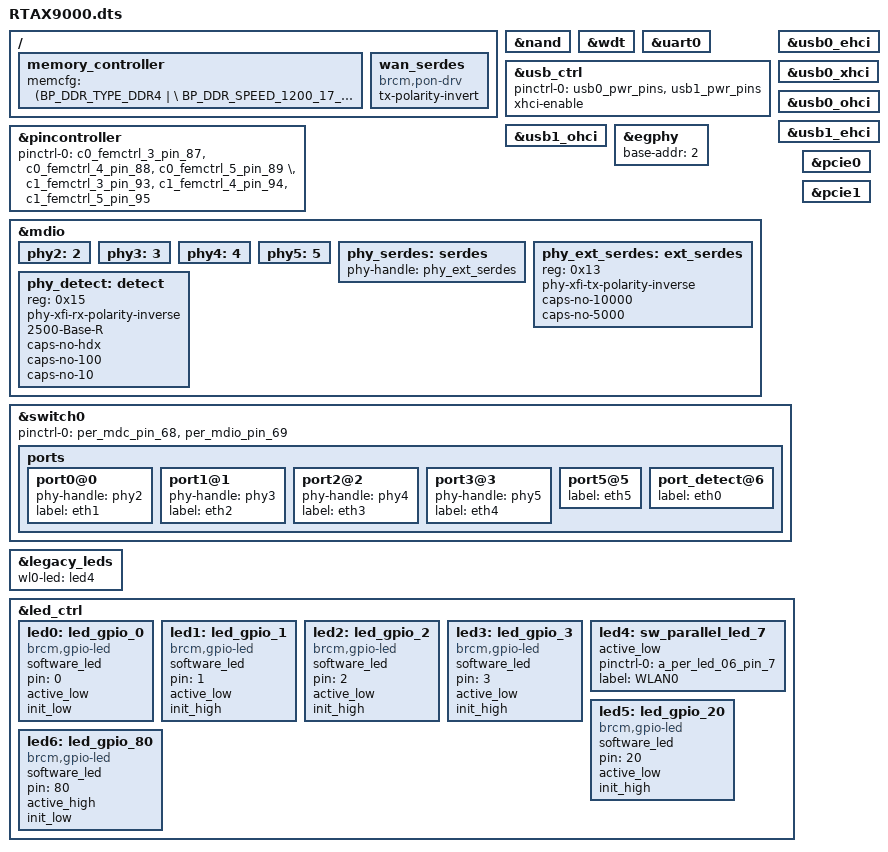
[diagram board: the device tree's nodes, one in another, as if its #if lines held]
#include "inc/6753.dtsi"

/ {
	memory_controller {
		memcfg = <(BP_DDR_TYPE_DDR4            | \
            BP_DDR_SPEED_1200_17_17_17         | \
            BP_DDR_TOTAL_SIZE_512MB            | \
            BP_DDR_DEVICE_WIDTH_16             | \
            BP_DDR_TOTAL_WIDTH_16BIT           | \
            BP_DDR_SSC_CONFIG_1)>;
	};
/*
    buttons {
        compatible = "brcm,buttons";
        reset_button {
            ext_irq = <&bca_extintr 15 BCA_GPIO_ACTIVE_LOW (BCA_EXTINTR_TYPE_LOW_LEVEL | BCA_EXTINTR_TYPE_SENSE_EDGE)>;
            press {
                print = "Button Press -- Hold for 5s to do restore to default";
            };
            hold {
                rst_to_dflt = <5>;
            };
            release {
                reset = <0>;
            };
        };
        ses_button {
            ext_irq = <&bca_extintr 14 BCA_GPIO_ACTIVE_LOW (BCA_EXTINTR_TYPE_LOW_LEVEL | BCA_EXTINTR_TYPE_SENSE_EDGE)>;
            release {
                ses_short_period = <0>;
                ses_long_period = <3>;
            };
        };
    };
*/
    wan_serdes {
        compatible = "brcm,pon-drv";
        tx-polarity-invert;
        status = "okay";
    };
};

&nand {
	status = "okay";
};
&wdt {
	status = "okay";
};
&uart0 {
	status = "okay";
};

&usb_ctrl {
    pinctrl-names = "default";
    pinctrl-0 = <&usb0_pwr_pins &usb1_pwr_pins>;
    xhci-enable;
    status = "okay";
};
&usb0_ehci {
    status = "okay";
};
&usb0_xhci {
    status = "okay";
};
&usb0_ohci {
    status = "okay";
};
&usb1_ehci {
    status = "okay";
};
&usb1_ohci {
    status = "okay";
};

&pincontroller {
    pinctrl-names = "default";
    pinctrl-0 = <&c0_femctrl_3_pin_87 &c0_femctrl_4_pin_88 &c0_femctrl_5_pin_89 \
                 &c1_femctrl_3_pin_93 &c1_femctrl_4_pin_94 &c1_femctrl_5_pin_95 >;
};

&egphy {
    base-addr = <2>;
};

&mdio {
    phy2:2 {
        status = "okay";
    };
    phy3:3 {
        status = "okay";
    };
    phy4:4 {
        status = "okay";
    };
    phy5:5 {
        status = "okay";
    };
    phy_serdes: serdes {
        phy-handle = <&phy_ext_serdes>;
        status = "okay";
    };
    phy_ext_serdes: ext_serdes {
        reg = <0x13>;
        phy-xfi-tx-polarity-inverse;
        caps-no-10000;
        caps-no-5000;
        status = "okay";
    };

    phy_detect:detect {
        reg = <0x15>;
        phy-xfi-rx-polarity-inverse;
        2500-Base-R;
        caps-no-hdx;
        caps-no-100;
        caps-no-10;
        status = "okay";
    };
};

&switch0 {
    pinctrl-names = "default";
    pinctrl-0 = <&per_mdc_pin_68 &per_mdio_pin_69>;
    ports {
        port0@0 {
            phy-handle = <&phy2>;
            status = "okay";
            label = "eth1";
        };

        port1@1 {
            phy-handle = <&phy3>;
            status = "okay";
            label = "eth2";
        };

        port2@2 {
            phy-handle = <&phy4>;
            status = "okay";
            label = "eth3";
        };

        port3@3 {
            phy-handle = <&phy5>;
            status = "okay";
            label = "eth4";
        };

        port5@5 {
            status = "okay";
            label = "eth5";
        };

        port_detect@6 {
            status = "okay";
            label = "eth0";
        };
    };
};

&legacy_leds {
    wl0-led = <&led4>;
};

&led_ctrl {
    status = "okay";

    /* POWER_LED */
    led0:led_gpio_0 {
        compatible = "brcm,gpio-led";
        software_led;
        pin = <0>;
        active_low;
        init_low;
    };

    /* LAN LED */
    led1:led_gpio_1 {
        compatible = "brcm,gpio-led";
        software_led;
        pin = <1>;
        active_low;
        init_high;
    };

    /* WPS LED */
    led2:led_gpio_2 {
        compatible = "brcm,gpio-led";
        software_led;
        pin = <2>;
        active_low;
        init_high;
    };

    /* WAN Red LED */
    led3:led_gpio_3 {
        compatible = "brcm,gpio-led";
        software_led;
        pin = <3>;
        active_low;
        init_high;
    };

    /* wl0 LED */
    led4: sw_parallel_led_7{
        active_low;
        pinctrl-0 = <&a_per_led_06_pin_7>;
        label = "WLAN0";
        status = "okay";
    };

    /* WAN LED GPIO mode */
    led5:led_gpio_20 {
        compatible = "brcm,gpio-led";
        software_led;
        pin = <20>;
        active_low;
        init_high;
    };

    /* USB Power */
    led6:led_gpio_80 {
        compatible = "brcm,gpio-led";
        software_led;
        pin = <80>;
        active_high;
        init_low;
    };
};

#if defined(CONFIG_BCM_PCIE_HCD) || defined(CONFIG_BCM_PCIE_HCD_MODULE)
&pcie0 {
    status = "okay";
};
&pcie1 {
    status = "okay";
};
#endif
